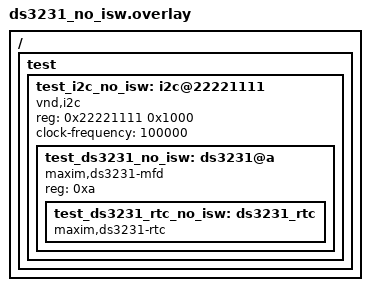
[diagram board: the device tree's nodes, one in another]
/*
 * Copyright (c) 2026 Sachin Pathave
 * SPDX-License-Identifier: Apache-2.0
 */

/*
 * Regression test for the DS3231 driver building without isw-gpios,
 * e.g. when the INT/SQW pin is intentionally left unconnected on the
 * board and only basic time get/set is needed.
 */

/ {
	test {
		#address-cells = <1>;
		#size-cells = <1>;

		test_i2c_no_isw: i2c@22221111 {
			#address-cells = <1>;
			#size-cells = <0>;
			compatible = "vnd,i2c";
			reg = <0x22221111 0x1000>;
			clock-frequency = <100000>;

			test_ds3231_no_isw: ds3231@a {
				compatible = "maxim,ds3231-mfd";
				reg = <0xa>;

				test_ds3231_rtc_no_isw: ds3231_rtc {
					compatible = "maxim,ds3231-rtc";
				};
			};
		};
	};
};
